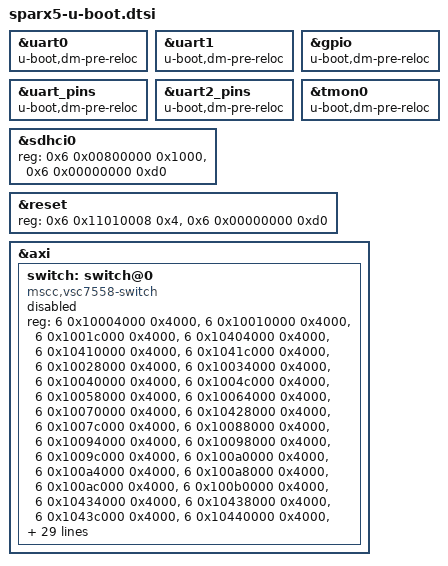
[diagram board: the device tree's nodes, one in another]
// SPDX-License-Identifier: GPL-2.0-or-later OR MIT

&uart0 {
	u-boot,dm-pre-reloc;
};

&uart1 {
	u-boot,dm-pre-reloc;
};

&gpio {
	u-boot,dm-pre-reloc;
};

&uart_pins {
	u-boot,dm-pre-reloc;
};

&uart2_pins {
	u-boot,dm-pre-reloc;
};

&tmon0 {
	u-boot,dm-pre-reloc;
};

&sdhci0 {
	/*
	 * Linux uses syscon to get the CPU regs, but
	 * we can avoid that by getting them directly.
	 */
	reg = <0x6 0x00800000 0x1000>, <0x6 0x00000000 0xd0>;
};

&reset {
	/*
	 * Linux uses syscon to get the CPU regs, but
	 * we can avoid that by getting them directly.
	 */
	reg = <0x6 0x11010008 0x4>, <0x6 0x00000000 0xd0>;
	reg-names = "gcb", "cpu";
};

/* We have to remove the Linux switch node */
/delete-node/ &switch;

&axi {
	switch: switch@0 {
		compatible = "mscc,vsc7558-switch";
		reg = <6 0x10004000 0x4000>,   // DEV2G5_0
		      <6 0x10010000 0x4000>,   // DEV2G5_1
		      <6 0x1001c000 0x4000>,   // DEV2G5_2
		      <6 0x10404000 0x4000>,   // DEV2G5_3
		      <6 0x10410000 0x4000>,   // DEV2G5_4
		      <6 0x1041c000 0x4000>,   // DEV2G5_5
		      <6 0x10028000 0x4000>,   // DEV2G5_6
		      <6 0x10034000 0x4000>,   // DEV2G5_7
		      <6 0x10040000 0x4000>,   // DEV2G5_8
		      <6 0x1004c000 0x4000>,   // DEV2G5_9
		      <6 0x10058000 0x4000>,   // DEV2G5_10
		      <6 0x10064000 0x4000>,   // DEV2G5_11
		      <6 0x10070000 0x4000>,   // DEV2G5_12
		      <6 0x10428000 0x4000>,   // DEV2G5_13
		      <6 0x1007c000 0x4000>,   // DEV2G5_14
		      <6 0x10088000 0x4000>,   // DEV2G5_15
		      <6 0x10094000 0x4000>,   // DEV2G5_16
		      <6 0x10098000 0x4000>,   // DEV2G5_17
		      <6 0x1009c000 0x4000>,   // DEV2G5_18
		      <6 0x100a0000 0x4000>,   // DEV2G5_19
		      <6 0x100a4000 0x4000>,   // DEV2G5_20
		      <6 0x100a8000 0x4000>,   // DEV2G5_21
		      <6 0x100ac000 0x4000>,   // DEV2G5_22
		      <6 0x100b0000 0x4000>,   // DEV2G5_23
		      <6 0x10434000 0x4000>,   // DEV2G5_24
		      <6 0x10438000 0x4000>,   // DEV2G5_25
		      <6 0x1043c000 0x4000>,   // DEV2G5_26
		      <6 0x10440000 0x4000>,   // DEV2G5_27
		      <6 0x10444000 0x4000>,   // DEV2G5_28
		      <6 0x10448000 0x4000>,   // DEV2G5_29
		      <6 0x1044c000 0x4000>,   // DEV2G5_30
		      <6 0x10450000 0x4000>,   // DEV2G5_31
		      <6 0x100b4000 0x4000>,   // DEV2G5_32
		      <6 0x100b8000 0x4000>,   // DEV2G5_33
		      <6 0x100bc000 0x4000>,   // DEV2G5_34
		      <6 0x100c0000 0x4000>,   // DEV2G5_35
		      <6 0x100c4000 0x4000>,   // DEV2G5_36
		      <6 0x100c8000 0x4000>,   // DEV2G5_37
		      <6 0x100cc000 0x4000>,   // DEV2G5_38
		      <6 0x100d0000 0x4000>,   // DEV2G5_39
		      <6 0x100d4000 0x4000>,   // DEV2G5_40
		      <6 0x100d8000 0x4000>,   // DEV2G5_41
		      <6 0x100dc000 0x4000>,   // DEV2G5_42
		      <6 0x100e0000 0x4000>,   // DEV2G5_43
		      <6 0x100e4000 0x4000>,   // DEV2G5_44
		      <6 0x100e8000 0x4000>,   // DEV2G5_45
		      <6 0x100ec000 0x4000>,   // DEV2G5_46
		      <6 0x100f0000 0x4000>,   // DEV2G5_47
		      <6 0x10454000 0x4000>,   // DEV2G5_48
		      <6 0x10460000 0x4000>,   // DEV2G5_49
		      <6 0x1046c000 0x4000>,   // DEV2G5_50
		      <6 0x10478000 0x4000>,   // DEV2G5_51
		      <6 0x10484000 0x4000>,   // DEV2G5_52
		      <6 0x10490000 0x4000>,   // DEV2G5_53
		      <6 0x1049c000 0x4000>,   // DEV2G5_54
		      <6 0x104a8000 0x4000>,   // DEV2G5_55
		      <6 0x104b4000 0x4000>,   // DEV2G5_56
		      <6 0x100f4000 0x4000>,   // DEV2G5_57
		      <6 0x104c4000 0x4000>,   // DEV2G5_58
		      <6 0x10104000 0x4000>,   // DEV2G5_59
		      <6 0x10114000 0x4000>,   // DEV2G5_60
		      <6 0x104d4000 0x4000>,   // DEV2G5_61
		      <6 0x104e4000 0x4000>,   // DEV2G5_62
		      <6 0x104f4000 0x4000>,   // DEV2G5_63
		      <6 0x10124000 0x4000>,   // DEV2G5_64
		      <6 0x11900000 0x100000>, // ANA_AC
		      <6 0x11400000 0x100000>, // ANA_CL
		      <6 0x11800000 0x100000>, // ANA_L2
		      <6 0x11480000 0x100000>, // ANA_L3
		      <6 0x10600000 0x10000>,  // ASM
		      <6 0x11060000 0x10000>,  // LRN
		      <6 0x110b0000 0x10000>,  // QFWD
		      <6 0x11030000 0x20000>,  // DEVCPU_QS
		      <6 0x110a0000 0x10000>,  // QSYS
		      <6 0x11600000 0x80000>,  // REW
		      <6 0x11a00000 0x80000>,  // VOP
		      <6 0x10504000 0x80000>,  // DSM
		      <6 0x112c0000 0x80000>,  // EACL
		      <6 0x11080000 0x80000>,  // VCAP_SUPER
		      <6 0x11580000 0x80000>,  // HSCH
		      <6 0x10130000 0x10000>;  // PORT_CONF
		reg-names = "port0", "port1", "port2", "port3",
		      "port4", "port5", "port6", "port7", "port8",
		      "port9", "port10", "port11", "port12", "port13",
		      "port14", "port15", "port16", "port17", "port18",
		      "port19", "port20", "port21", "port22", "port23",
		      "port24", "port25", "port26", "port27", "port28",
		      "port29", "port30", "port31", "port32", "port33",
		      "port34",	"port35", "port36", "port37", "port38",
		      "port39", "port40", "port41", "port42", "port43",
		      "port44", "port45", "port46", "port47", "port48",
		      "port49", "port50", "port51", "port52", "port53",
		      "port54", "port55", "port56", "port57", "port58",
		      "port59", "port60", "port61", "port62", "port63",
		      "port64",
		      "ana_ac", "ana_cl",
		      "ana_l2", "ana_l3", "asm", "lrn", "qfwd",
		      "qs", "qsys", "rew",
		      "vop", "dsm", "eacl", "vcap_super",
		      "hsch", "port_conf";
		resets = <&reset 0>;
		reset-names = "switch";
		status = "disabled";
	};
};
